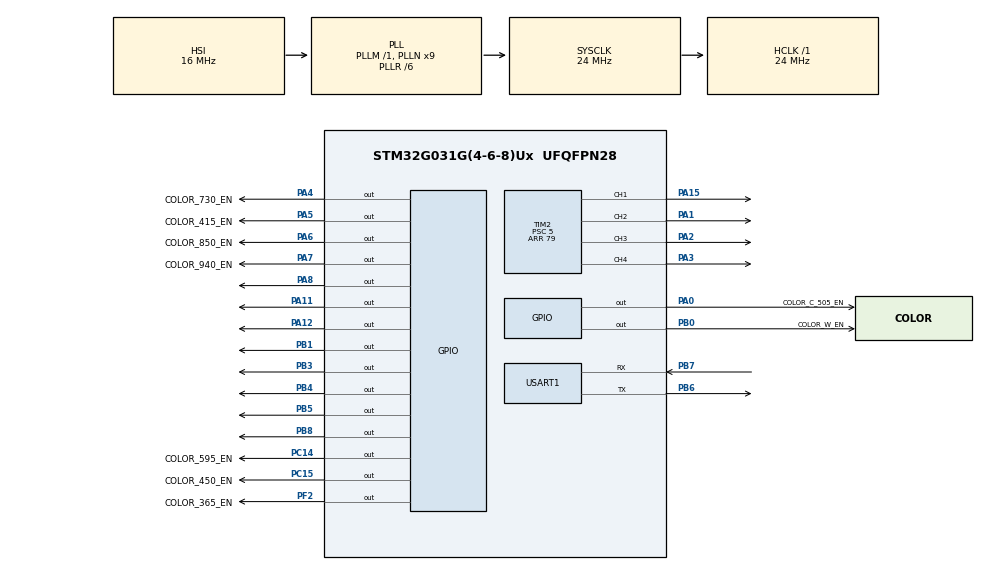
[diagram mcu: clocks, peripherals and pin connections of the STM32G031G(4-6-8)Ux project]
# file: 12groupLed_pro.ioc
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Mcu.Family=STM32G0
Mcu.Name=STM32G031G(4-6-8)Ux
Mcu.Package=UFQFPN28
NVIC.USART1_IRQn=true\:0\:0\:false\:false\:true\:true\:true
PA0.GPIO_Label=COLOR_C_505_EN
PA0.GPIO_PuPd=GPIO_PULLUP
PA0.Signal=GPIO_Output
PA1.Signal=S_TIM2_CH2
PA11\ [PA9].GPIO_PuPd=GPIO_PULLUP
PA11\ [PA9].Signal=GPIO_Output
PA12\ [PA10].GPIO_PuPd=GPIO_PULLUP
PA12\ [PA10].Signal=GPIO_Output
PA15.Signal=S_TIM2_CH1
PA2.Signal=S_TIM2_CH3
PA3.Signal=S_TIM2_CH4
PA4.GPIO_Label=COLOR_730_EN
PA4.GPIO_PuPd=GPIO_PULLUP
PA4.Signal=GPIO_Output
PA5.GPIO_Label=COLOR_415_EN
PA5.GPIO_PuPd=GPIO_PULLUP
PA5.Signal=GPIO_Output
PA6.GPIO_Label=COLOR_850_EN
PA6.GPIO_PuPd=GPIO_PULLUP
PA6.Signal=GPIO_Output
PA7.GPIO_Label=COLOR_940_EN
PA7.GPIO_PuPd=GPIO_PULLUP
PA7.Signal=GPIO_Output
PA8.GPIO_PuPd=GPIO_PULLUP
PA8.Signal=GPIO_Output
PB0.GPIO_Label=COLOR_W_EN
PB0.GPIO_PuPd=GPIO_PULLUP
PB0.Signal=GPIO_Output
PB1.GPIO_PuPd=GPIO_PULLUP
PB1.Signal=GPIO_Output
PB3.GPIO_PuPd=GPIO_PULLUP
PB3.Signal=GPIO_Output
PB4.GPIO_PuPd=GPIO_PULLUP
PB4.Signal=GPIO_Output
PB5.GPIO_PuPd=GPIO_PULLUP
PB5.Signal=GPIO_Output
PB6.Mode=Asynchronous
PB6.Signal=USART1_TX
PB7.Mode=Asynchronous
PB7.Signal=USART1_RX
PB8.GPIO_PuPd=GPIO_PULLUP
PB8.Signal=GPIO_Output
PC14-OSC32_IN\ (PC14).GPIO_Label=COLOR_595_EN
PC14-OSC32_IN\ (PC14).GPIO_PuPd=GPIO_PULLUP
PC14-OSC32_IN\ (PC14).Signal=GPIO_Output
PC15-OSC32_OUT\ (PC15).GPIO_Label=COLOR_450_EN
PC15-OSC32_OUT\ (PC15).GPIO_PuPd=GPIO_PULLUP
PC15-OSC32_OUT\ (PC15).Signal=GPIO_Output
PF2\ -\ NRST.GPIO_Label=COLOR_365_EN
PF2\ -\ NRST.GPIO_PuPd=GPIO_PULLUP
PF2\ -\ NRST.Signal=GPIO_Output
ProjectManager.HeapSize=0x200
ProjectManager.StackSize=0x400
ProjectManager.TargetToolchain=MDK-ARM V5.27
RCC.ADCFreq_Value=24000000
RCC.AHBFreq_Value=24000000
RCC.CortexFreq_Value=24000000
RCC.EXTERNAL_CLOCK_VALUE=12288000
RCC.HCLKFreq_Value=24000000
RCC.HSE_VALUE=8000000
RCC.HSI_VALUE=16000000
RCC.LSE_VALUE=32768
RCC.PLLN=9
RCC.PLLR=RCC_PLLR_DIV6
RCC.SYSCLKFreq_VALUE=24000000
RCC.SYSCLKSource=RCC_SYSCLKSOURCE_PLLCLK
RCC.VCOOutputFreq_Value=144000000
SH.S_TIM2_CH1.0=TIM2_CH1,PWM Generation1 CH1
SH.S_TIM2_CH2.0=TIM2_CH2,PWM Generation2 CH2
SH.S_TIM2_CH3.0=TIM2_CH3,PWM Generation3 CH3
SH.S_TIM2_CH4.0=TIM2_CH4,PWM Generation4 CH4
TIM2.Channel-PWM\ Generation1\ CH1=TIM_CHANNEL_1
TIM2.Channel-PWM\ Generation2\ CH2=TIM_CHANNEL_2
TIM2.Channel-PWM\ Generation3\ CH3=TIM_CHANNEL_3
TIM2.Channel-PWM\ Generation4\ CH4=TIM_CHANNEL_4
TIM2.Period=79
TIM2.Prescaler=5
USART1.VirtualMode-Asynchronous=VM_ASYNC
VP_TIM2_VS_ClockSourceINT.Mode=Internal
board=custom

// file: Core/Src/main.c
/* USER CODE BEGIN Header */
/**
  ******************************************************************************
  * @file           : main.c
  * @brief          : Main program body
  ******************************************************************************
  * @attention
  *
  * <h2><center>&copy; Copyright (c) 2021 STMicroelectronics.
  * All rights reserved.</center></h2>
  *
  * This software component is licensed by ST under BSD 3-Clause license,
  * the "License"; You may not use this file except in compliance with the
  * License. You may obtain a copy of the License at:
  *                        opensource.org/licenses/BSD-3-Clause
  *
  ******************************************************************************
  */
/* USER CODE END Header */
#include "main.h"
#include "tim.h"
#include "usart.h"
#include "gpio.h"

/* USER CODE BEGIN Includes */
#include "run.h"
#include "led.h"
/* USER CODE END Includes */

/* USER CODE BEGIN PD */
uint8_t aRxBuffer[RXBUFFERSIZE];
/* USER CODE END PD */

void SystemClock_Config(void);

int main(void)
{

  /* MCU Configuration--------------------------------------------------------*/

  /* Reset of all peripherals, Initializes the Flash interface and the Systick. */
  HAL_Init();

  /* Configure the system clock */
  SystemClock_Config();

  /* Initialize all configured peripherals */
  MX_GPIO_Init();
  MX_TIM2_Init();
  MX_USART1_UART_Init();
  /* USER CODE BEGIN 2 */
  HAL_UART_Abort(&huart1);
	HAL_UART_Receive_IT(&huart1,aRxBuffer,1);
  /* USER CODE END 2 */

  /* Infinite loop */
  /* USER CODE BEGIN WHILE */
  while (1)
  {

	      DecodeCommand();
    /* USER CODE END WHILE */

  }
}

void SystemClock_Config(void)
{
  RCC_OscInitTypeDef RCC_OscInitStruct = {0};
  RCC_ClkInitTypeDef RCC_ClkInitStruct = {0};
  RCC_PeriphCLKInitTypeDef PeriphClkInit = {0};

  /** Configure the main internal regulator output voltage
  */
  HAL_PWREx_ControlVoltageScaling(PWR_REGULATOR_VOLTAGE_SCALE1);
  /** Initializes the RCC Oscillators according to the specified parameters
  * in the RCC_OscInitTypeDef structure.
  */
  RCC_OscInitStruct.OscillatorType = RCC_OSCILLATORTYPE_HSI;
  RCC_OscInitStruct.HSIState = RCC_HSI_ON;
  RCC_OscInitStruct.HSIDiv = RCC_HSI_DIV1;
  RCC_OscInitStruct.HSICalibrationValue = RCC_HSICALIBRATION_DEFAULT;
  RCC_OscInitStruct.PLL.PLLState = RCC_PLL_ON;
  RCC_OscInitStruct.PLL.PLLSource = RCC_PLLSOURCE_HSI;
  RCC_OscInitStruct.PLL.PLLM = RCC_PLLM_DIV1;
  RCC_OscInitStruct.PLL.PLLN = 9;
  RCC_OscInitStruct.PLL.PLLP = RCC_PLLP_DIV2;
  RCC_OscInitStruct.PLL.PLLQ = RCC_PLLQ_DIV2;
  RCC_OscInitStruct.PLL.PLLR = RCC_PLLR_DIV6;
  if (HAL_RCC_OscConfig(&RCC_OscInitStruct) != HAL_OK)
  {
    Error_Handler();
  }
  /** Initializes the CPU, AHB and APB buses clocks
  */
  RCC_ClkInitStruct.ClockType = RCC_CLOCKTYPE_HCLK|RCC_CLOCKTYPE_SYSCLK
                              |RCC_CLOCKTYPE_PCLK1;
  RCC_ClkInitStruct.SYSCLKSource = RCC_SYSCLKSOURCE_PLLCLK;
  RCC_ClkInitStruct.AHBCLKDivider = RCC_SYSCLK_DIV1;
  RCC_ClkInitStruct.APB1CLKDivider = RCC_HCLK_DIV1;

  if (HAL_RCC_ClockConfig(&RCC_ClkInitStruct, FLASH_LATENCY_0) != HAL_OK)
  {
    Error_Handler();
  }
  /** Initializes the peripherals clocks
  */
  PeriphClkInit.PeriphClockSelection = RCC_PERIPHCLK_USART1;
  PeriphClkInit.Usart1ClockSelection = RCC_USART1CLKSOURCE_PCLK1;
  if (HAL_RCCEx_PeriphCLKConfig(&PeriphClkInit) != HAL_OK)
  {
    Error_Handler();
  }
}

void Error_Handler(void)
{
  __disable_irq();
  while (1)
  {
  }
}

/************************ (C) COPYRIGHT STMicroelectronics *****END OF FILE****/
